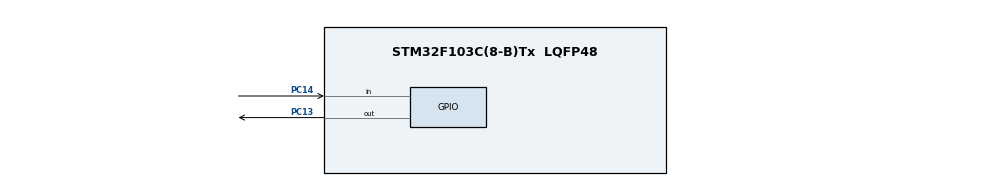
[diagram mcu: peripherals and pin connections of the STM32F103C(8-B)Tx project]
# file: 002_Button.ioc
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Mcu.Family=STM32F1
Mcu.Name=STM32F103C(8-B)Tx
Mcu.Package=LQFP48
NVIC.PriorityGroup=NVIC_PRIORITYGROUP_4
PA13.Mode=Serial_Wire
PA13.Signal=SYS_JTMS-SWDIO
PA14.Mode=Serial_Wire
PA14.Signal=SYS_JTCK-SWCLK
PC13-TAMPER-RTC.Signal=GPIO_Output
PC14-OSC32_IN.GPIO_PuPd=GPIO_PULLUP
PC14-OSC32_IN.Signal=GPIO_Input
ProjectManager.HeapSize=0x200
ProjectManager.StackSize=0x400
ProjectManager.TargetToolchain=MDK-ARM V5.27
RCC.APB1Freq_Value=8000000
RCC.APB2Freq_Value=8000000
board=custom

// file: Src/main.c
/* USER CODE BEGIN Header */
/**
  ******************************************************************************
  * @file           : main.c
  * @brief          : Main program body
  ******************************************************************************
  * @attention
  *
  * <h2><center>&copy; Copyright (c) 2023 STMicroelectronics.
  * All rights reserved.</center></h2>
  *
  * This software component is licensed by ST under BSD 3-Clause license,
  * the "License"; You may not use this file except in compliance with the
  * License. You may obtain a copy of the License at:
  *                        opensource.org/licenses/BSD-3-Clause
  *
  ******************************************************************************
  */
/* USER CODE END Header */

#include "main.h"

void SystemClock_Config(void);
static void MX_GPIO_Init(void);

int main(void)
{

  /* MCU Configuration--------------------------------------------------------*/

  /* Reset of all peripherals, Initializes the Flash interface and the Systick. */

  LL_APB2_GRP1_EnableClock(LL_APB2_GRP1_PERIPH_AFIO);
  LL_APB1_GRP1_EnableClock(LL_APB1_GRP1_PERIPH_PWR);

  NVIC_SetPriorityGrouping(NVIC_PRIORITYGROUP_4);

  /* System interrupt init*/

  /** NOJTAG: JTAG-DP Disabled and SW-DP Enabled
  */
  LL_GPIO_AF_Remap_SWJ_NOJTAG();

  /* Configure the system clock */
  SystemClock_Config();

  /* Initialize all configured peripherals */
  MX_GPIO_Init();

  /* Infinite loop */
  /* USER CODE BEGIN WHILE */
  while (1)
  {
		 if(!LL_GPIO_IsInputPinSet(GPIOC, LL_GPIO_PIN_14)) // проверяем, присутствует ли лог. 1 на пине 14
			 LL_GPIO_ResetOutputPin(GPIOC, LL_GPIO_PIN_13); // выполнение только тогда, когда будет лог. 0, т.е. когда кнопка нажата -> включаем светодиод
		 else LL_GPIO_SetOutputPin(GPIOC, LL_GPIO_PIN_13); //выключаем светодиод
    /* USER CODE END WHILE */

  }
}

void SystemClock_Config(void)
{
  LL_FLASH_SetLatency(LL_FLASH_LATENCY_0);

  if(LL_FLASH_GetLatency() != LL_FLASH_LATENCY_0)
  {
    Error_Handler();
  }
  LL_RCC_HSI_SetCalibTrimming(16);
  LL_RCC_HSI_Enable();

   /* Wait till HSI is ready */
  while(LL_RCC_HSI_IsReady() != 1)
  {

  }
  LL_RCC_SetAHBPrescaler(LL_RCC_SYSCLK_DIV_1);
  LL_RCC_SetAPB1Prescaler(LL_RCC_APB1_DIV_1);
  LL_RCC_SetAPB2Prescaler(LL_RCC_APB2_DIV_1);
  LL_RCC_SetSysClkSource(LL_RCC_SYS_CLKSOURCE_HSI);

   /* Wait till System clock is ready */
  while(LL_RCC_GetSysClkSource() != LL_RCC_SYS_CLKSOURCE_STATUS_HSI)
  {

  }
  LL_Init1msTick(8000000);
  LL_SetSystemCoreClock(8000000);
}

static void MX_GPIO_Init(void)
{
  LL_GPIO_InitTypeDef GPIO_InitStruct = {0};

  /* GPIO Ports Clock Enable */
  LL_APB2_GRP1_EnableClock(LL_APB2_GRP1_PERIPH_GPIOC);
  LL_APB2_GRP1_EnableClock(LL_APB2_GRP1_PERIPH_GPIOA);

  /**/
  LL_GPIO_ResetOutputPin(GPIOC, LL_GPIO_PIN_13);

  /**/
  GPIO_InitStruct.Pin = LL_GPIO_PIN_13;
  GPIO_InitStruct.Mode = LL_GPIO_MODE_OUTPUT;
  GPIO_InitStruct.Speed = LL_GPIO_SPEED_FREQ_LOW;
  GPIO_InitStruct.OutputType = LL_GPIO_OUTPUT_PUSHPULL;
  LL_GPIO_Init(GPIOC, &GPIO_InitStruct);

  /**/
  GPIO_InitStruct.Pin = LL_GPIO_PIN_14;
  GPIO_InitStruct.Mode = LL_GPIO_MODE_INPUT;
  GPIO_InitStruct.Pull = LL_GPIO_PULL_UP;
  LL_GPIO_Init(GPIOC, &GPIO_InitStruct);

}

void Error_Handler(void)
{
}

/************************ (C) COPYRIGHT STMicroelectronics *****END OF FILE****/
